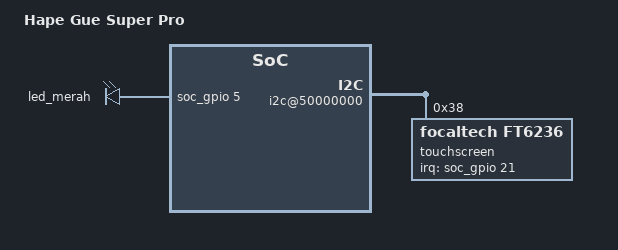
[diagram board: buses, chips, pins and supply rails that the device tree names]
// File: hape-gue.dts (Ini file custom kita)

/dts-v1/;

// 1. KITA "PLEK KETIPLEK" (INCLUDE) FILE PABRIK
/include/ "chipset-inti.dtsi"

// 2. KITA TAMBAHKAN IDENTITAS BOARD KITA
/ {
    model = "Hape Gue Super Pro";
    compatible = "hapegue,super-pro", "pabrik,chipset-inti";

    // 3. KITA TAMBAHKAN NODE BARU (Lampu LED)
    leds {
        compatible = "gpio-leds";
        
        lampu_notifikasi {
            label = "led_merah";
            gpios = <&soc_gpio 5 0>; 
            linux,default-trigger = "timer";
        };
    };

    // --- PERBAIKAN 1: I2C DIMASUKKAN KE DALAM SINI ---
    i2c@50000000 {
        // PERBAIKAN 2: Spasi setelah koma dihapus
        compatible = "pabrik,i2c-controller"; 
        reg = <0x50000000 0x1000>;
        
        #address-cells = <1>;
        #size-cells = <0>;
        status = "okay";

        touchscreen@38 {
            // PERBAIKAN 2: Spasi setelah koma dihapus
            compatible = "focaltech,ft6236"; 
            reg = <0x38>;

            interrupt-parent = <&soc_gpio>; 
            // PERBAIKAN 3: Dikembalikan pakai "interrupts"
            interrupts = <21 2>; 

            touchscreen-size-x = <720>;
            touchscreen-size-y = <1280>;
        };
    };
}; // <-- INI PENUTUP ROOT NODE ( / ) YANG BENAR

// 4. KITA OVERRIDE (TIMPA) NILAI BAWAAN PABRIK (Selalu di luar Root)

&{/memory@80000000} {
    reg = <0x80000000 0x40000000>; 
};

&soc_gpio {
    status = "okay";
};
